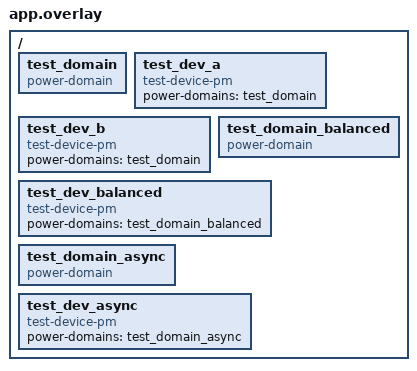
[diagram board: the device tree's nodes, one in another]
/*
 * Copyright (c) 2021 Intel Corporation
 *
 * SPDX-License-Identifier: Apache-2.0
 */

/ {
	test_domain: test_domain {
		compatible = "power-domain";
		#power-domain-cells = <0>;
		status = "okay";
	};

	test_dev_a: test_dev_a {
		compatible = "test-device-pm";
		power-domains = <&test_domain>;
		status = "okay";
	};

	test_dev_b: test_dev_b {
		compatible = "test-device-pm";
		power-domains = <&test_domain>;
		status = "okay";
	};

	test_domain_balanced: test_domain_balanced {
		compatible = "power-domain";
		#power-domain-cells = <0>;
		status = "okay";
	};

	test_dev_balanced: test_dev_balanced {
		compatible = "test-device-pm";
		power-domains = <&test_domain_balanced>;
		status = "okay";
	};

	test_domain_async: test_domain_async {
		compatible = "power-domain";
		#power-domain-cells = <0>;
		status = "okay";
	};

	test_dev_async: test_dev_async {
		compatible = "test-device-pm";
		power-domains = <&test_domain_async>;
		status = "okay";
	};
};
